# DP32G030 register map
File version: 1.0
CPU: CM0 r0p0, little endian, no MPU, no FPU, 4 interrupt priority bits
Registers are 32-bit, read-write, reset 0x0 unless marked. A register's access mark holds for its fields unless they carry their own. Offsets are from the block's base; [hi:lo] are bit positions; {n}, {i} and the like mark numbered series.

## GPIOC — GPIOC unit
Base 0x40061000
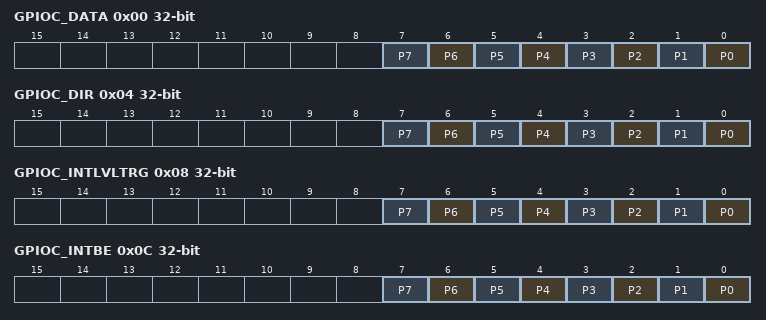
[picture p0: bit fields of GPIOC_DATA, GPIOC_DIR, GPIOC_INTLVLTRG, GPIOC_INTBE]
0x00 GPIOC_DATA — GPIO DATA register
  [n] P{n} (n=0..7)
0x04 GPIOC_DIR — GPIO Pin direction
  [n] P{n} (n=0..7) — Sets the GPIO pin direction: 1: Set the GPIO pin of the corresponding bit as output pin 0: Set the GPIO pin of the corresponding bit as input pin
0x08 GPIOC_INTLVLTRG — GPIO Pin interrupt sensitive conditions
  [n] P{n} (n=0..7) — Sets the GPIO pin interrupt sensitivity condition: 1: Set the GPIO pin of the corresponding bit as level detection 0: Set the GPIO pin of the corresponding bit as Along Detect
0x0C GPIOC_INTBE — GPIO Pin edge trigger mode
  [n] P{n} (n=0..7) — Sets the GPIO pin edge trigger method: 1: Set the GPIO pin of the corresponding bit to double- edge triggered interrupt, i.e., both the rising and falling edges will trigger the interrupt 0: Set the GPIO pin of the corresponding bit to single-edge trigger interrupt, the corresponding bit of INTRISEEN register determines the rising/falling edge trigger.
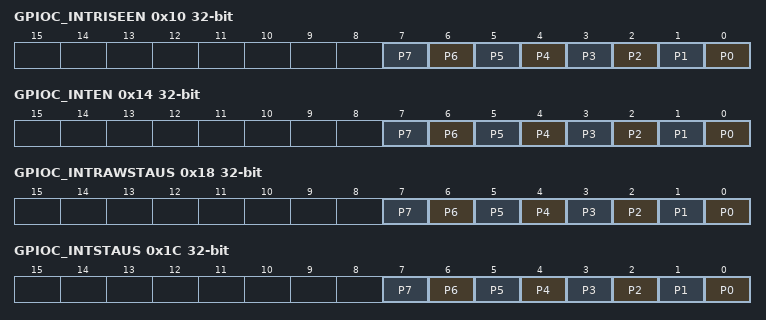
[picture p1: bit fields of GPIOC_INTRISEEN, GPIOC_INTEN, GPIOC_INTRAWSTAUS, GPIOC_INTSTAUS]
0x10 GPIOC_INTRISEEN — GPIO Pin interrupt event mode
  [n] P{n} (n=0..7) — Sets the GPIO pin interrupt event mode: 1: Set the GPIO pin of the corresponding bit to trigger an interrupt with a rising edge/high level. 0: Set the GPIO pin of the corresponding bit as falling edge/low level trigger interrupt
0x14 GPIOC_INTEN — GPIO Pin interrupt enable
  [n] P{n} (n=0..7) — Sets the GPIO pin interrupt enable: 1: Set the GPIO pin interrupt enable for the corresponding bit. 0: Set the GPIO pin interrupt disable for the corresponding bit.
0x18 GPIOC_INTRAWSTAUS ro — Indicates that the corresponding bit is detectedGPIO interrupt trigger
  [n] P{n} (n=0..7) — When the GPIO is configured in input mode, the interrupt flag is generated according to the set trigger condition, independent of the interrupt enable register. Set by hardware and cleared by software by writing 1 to GPIOIC. 1: Indicates that the GPIO interrupt trigger condition for the corresponding bit is detected (raw, before mask) 0: Indicates that no GPIO interrupt trigger condition is detected for the corresponding bit.
0x1C GPIOC_INTSTAUS ro — Indicates that the corresponding bit is detectedGPIO pin generation int
  [n] P{n} (n=0..7) — When the GPIO is configured in input mode and the interrupt of the corresponding bit is enabled, an interrupt flag is generated according to the set trigger condition. It is set by hardware and cleared by software by writing 1 to the GPIOIC. 1: Indicates that an interrupt generated by the GPIO pin of the corresponding bit is detected (after the mask) 0: Indicates that no interrupt generated by the GPIO pin of the corresponding bit is detected
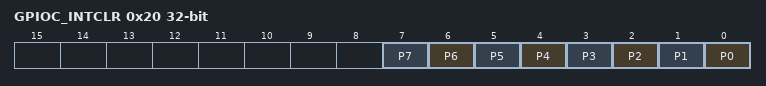
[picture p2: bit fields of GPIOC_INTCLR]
0x20 GPIOC_INTCLR wo — Clear the corresponding bitGPIOsPin edge triggered interrupt flag
  [n] P{n} (n=0..7) — Write 1: Clear the corresponding bit of GPIO Pin Along Trigger Interrupt Flag. INTRAWSTAUS and INTSTAUS. clear interrupts After the flag, the corresponding bit of INTCLR is automatically restored to 0 by the hardware. Write 0: no effect. A read operation on this register returns 0.

## TIMER_BASE0 — TIMER_BASE0 unit
Base 0x40064000
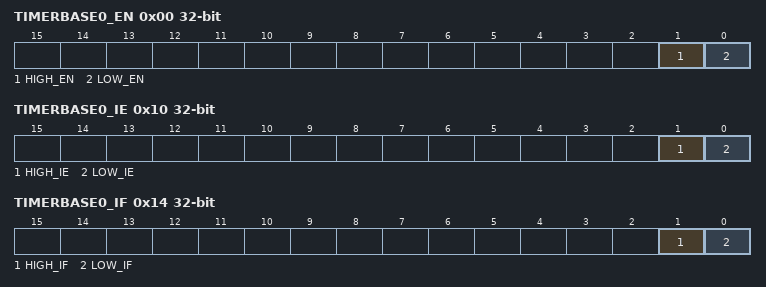
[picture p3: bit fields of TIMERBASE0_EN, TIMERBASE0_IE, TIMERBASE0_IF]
0x00 TIMERBASE0_EN — TIMER enable register
  [1] HIGH_EN — TIMERBASE HIGH Timer Enable Register
  [0] LOW_EN — TIMERBASE LOW Timer Enable Register
0x04 TIMERBASE0_DIV — TIMER Count Clock Divider Register
  [15:0] DIV — TIMERBASE Count Clock Prescaler Register 0x0000: indicates 1 division 0x0001: indicates 2 divisions ...... 0xFFFF: indicates 65536 division frequency
0x10 TIMERBASE0_IE — TIMER interrupt enable register
  [1] HIGH_IE — TIMERBASE HIGH Timer Interrupt Enable
  [0] LOW_IE — TIMERBASE LOW Timer Interrupt Enable
0x14 TIMERBASE0_IF — TIMER Interrupt Status Register
  [1] HIGH_IF — TIMERBASE HIGH Timer Interrupt Status Write 1 to clear the status.
  [0] LOW_IF — TIMERBASE LOW Timer Interrupt Status Write 1 to Clear
0x20 TIMERBASE0_HIGH_LOAD reset 0xFFFF — TIMER HIGH target configuration register
  [15:0] HIGH_LOAD — TIMERBASE HIGH Timer Target Configuration Register When the high 16bit counter counts up to the set value, the corresponding status signal is generated.
0x24 TIMERBASE0_HIGH_CNT ro — TIMER HIGH Current count value register
  [15:0] HIGH_CNT — TIMERBASE HIGH Timer Current Count Value
0x30 TIMERBASE0_LOW_LOAD reset 0xFFFF — TIMER LOW target configuration register
  [15:0] LOW_LOAD — TIMERBASE LOW Timer Target Configuration Register When the low 16bit counter counts up to the set value, the corresponding status signal is generated.
0x34 TIMERBASE0_LOW_CNT ro — TIMER LOW Current count value register
  [15:0] LOW_CNT — TIMERBASE LOW Timer Current Count Value
